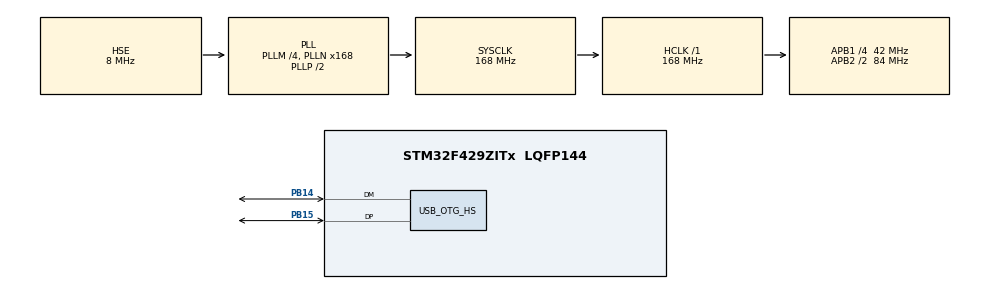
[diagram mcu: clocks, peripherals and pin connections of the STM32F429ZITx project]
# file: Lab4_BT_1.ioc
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FREERTOS.Tasks01=Task01,0,256,StartTask01,Default,NULL,Dynamic,NULL,NULL;Task02,0,128,StartTask02,Default,NULL,Dynamic,NULL,NULL
Mcu.Family=STM32F4
Mcu.Name=STM32F429ZITx
Mcu.Package=LQFP144
NVIC.OTG_HS_IRQn=true\:5\:0\:false\:false\:true\:true\:true\:true\:true
NVIC.PriorityGroup=NVIC_PRIORITYGROUP_4
NVIC.TIM6_DAC_IRQn=true\:15\:0\:false\:false\:true\:false\:false\:true\:true
NVIC.TimeBase=TIM6_DAC_IRQn
NVIC.TimeBaseIP=TIM6
PA13.Mode=Serial_Wire
PA13.Signal=SYS_JTMS-SWDIO
PA14.Mode=Serial_Wire
PA14.Signal=SYS_JTCK-SWCLK
PB14.Mode=Device_Only_FS
PB14.Signal=USB_OTG_HS_DM
PB15.Mode=Device_Only_FS
PB15.Signal=USB_OTG_HS_DP
PH0/OSC_IN.Mode=HSE-External-Oscillator
PH0/OSC_IN.Signal=RCC_OSC_IN
PH1/OSC_OUT.Mode=HSE-External-Oscillator
PH1/OSC_OUT.Signal=RCC_OSC_OUT
ProjectManager.HeapSize=0x2000
ProjectManager.StackSize=0x400
ProjectManager.TargetToolchain=STM32CubeIDE
RCC.48MHZClocksFreq_Value=48000000
RCC.AHBFreq_Value=168000000
RCC.APB1CLKDivider=RCC_HCLK_DIV4
RCC.APB1Freq_Value=42000000
RCC.APB1TimFreq_Value=84000000
RCC.APB2CLKDivider=RCC_HCLK_DIV2
RCC.APB2Freq_Value=84000000
RCC.APB2TimFreq_Value=168000000
RCC.CortexFreq_Value=168000000
RCC.HCLKFreq_Value=168000000
RCC.HSE_VALUE=8000000
RCC.HSI_VALUE=16000000
RCC.LSE_VALUE=32768
RCC.PLLM=4
RCC.PLLN=168
RCC.PLLQ=7
RCC.SYSCLKFreq_VALUE=168000000
RCC.SYSCLKSource=RCC_SYSCLKSOURCE_PLLCLK
RCC.VCOOutputFreq_Value=336000000
USB_DEVICE.CLASS_NAME_HS=CDC
USB_DEVICE.VirtualMode-CDC_HS=Cdc
USB_DEVICE.VirtualModeHS=Cdc_HS
USB_OTG_HS.VirtualMode-Device_Only_FS=Device_Only_FS
VP_FREERTOS_VS_CMSIS_V1.Mode=CMSIS_V1
VP_SYS_VS_tim6.Mode=TIM6
VP_USB_DEVICE_VS_USB_DEVICE_CDC_HS.Mode=CDC_HS
board=custom

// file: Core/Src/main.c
/* USER CODE BEGIN Header */
/**
  ******************************************************************************
  * @file           : main.c
  * @brief          : Main program body
  ******************************************************************************
  * @attention
  *
  * Copyright (c) 2023 STMicroelectronics.
  * All rights reserved.
  *
  * This software is licensed under terms that can be found in the LICENSE file
  * in the root directory of this software component.
  * If no LICENSE file comes with this software, it is provided AS-IS.
  *
  ******************************************************************************
  */
/* USER CODE END Header */
#include "main.h"
#include "cmsis_os.h"
#include "usb_device.h"

/* USER CODE BEGIN Includes */
#include "string.h"
#include "stm32f429i_discovery_sdram.h"
#include "stm32f429i_discovery_lcd.h"
#include "usbd_cdc_if.h"
#include "stm32f429i_discovery_gyroscope.h"
#include "stm32f429i_discovery_io.h"
#include <stdio.h>
/* USER CODE END Includes */

osThreadId Task01Handle;
osThreadId Task02Handle;
/* USER CODE BEGIN PV */
//float valxyz[3];
//uint8_t transmit_d[64];
volatile uint32_t value;
//uint8_t buffer[200];//text buffer

osMailQId(myMailQID);
/* USER CODE END PV */

void SystemClock_Config(void);
static void MX_GPIO_Init(void);
void StartTask01(void const * argument);
void StartTask02(void const * argument);

int main(void)
{

  /* MCU Configuration--------------------------------------------------------*/

  /* Reset of all peripherals, Initializes the Flash interface and the Systick. */
  HAL_Init();

  /* Configure the system clock */
  SystemClock_Config();

  /* Initialize all configured peripherals */
  MX_GPIO_Init();
  /* USER CODE BEGIN 2 */
  BSP_SDRAM_Init();
  *((uint32_t*)SDRAM_DEVICE_ADDR)=0x12345678;
  value=*((uint32_t*)SDRAM_DEVICE_ADDR);
  BSP_LCD_Init();
  BSP_GYRO_Init();
  BSP_LCD_LayerDefaultInit(1, SDRAM_DEVICE_ADDR);
  BSP_LCD_SelectLayer(1);//select on which layer we
  BSP_LCD_DisplayOn();//turn on LCD
  BSP_LCD_Clear(LCD_COLOR_BLACK);//clear the LCD on blACK
  BSP_LCD_SetBackColor(LCD_COLOR_BLACK);//set text background color
  BSP_LCD_SetTextColor(LCD_COLOR_WHITE);//set text color
  /* USER CODE END 2 */

  /* USER CODE BEGIN RTOS_QUEUES */
  /* add queues, ... */

  osMailQDef( myMailQ, 3, float );

  myMailQID = osMailCreate(osMailQ(myMailQ), NULL);

  /* USER CODE END RTOS_QUEUES */

  /* Create the thread(s) */
  /* definition and creation of Task01 */
  osThreadDef(Task01, StartTask01, osPriorityNormal, 0, 256);
  Task01Handle = osThreadCreate(osThread(Task01), NULL);

  /* definition and creation of Task02 */
  osThreadDef(Task02, StartTask02, osPriorityNormal, 0, 128);
  Task02Handle = osThreadCreate(osThread(Task02), NULL);

  /* Start scheduler */
  osKernelStart();

  /* We should never get here as control is now taken by the scheduler */
  /* Infinite loop */
  /* USER CODE BEGIN WHILE */
  while (1)
  {
//
//	  HAL_Delay(1000);
//	  BSP_GYRO_GetXYZ(valxyz);
//	  sprintf(buffer,"xyz:	%f	%f	%f\r\n",valxyz[0],valxyz[1],valxyz[2]);
//	  CDC_Transmit_HS(buffer,64);
//
//
//	  if ((valxyz[0]<0) && (valxyz[1]<0) && (valxyz[2] > 0)){
//		  BSP_LCD_Clear(LCD_COLOR_BLACK);//clear the LCD on blACK
//		  BSP_LCD_DisplayStringAtLine(1,"      ^");
//		  BSP_LCD_DisplayStringAtLine(4,"<");
//	  } else if ((valxyz[0]<0) && (valxyz[1]>0) && (valxyz[2] < 0)){
//		  BSP_LCD_Clear(LCD_COLOR_BLACK);//clear the LCD on blACK
//		  BSP_LCD_DisplayStringAtLine(1,"      ^");
//		  BSP_LCD_DisplayStringAtLine(4,"             >");
//	  } else if (valxyz[0]>0 && valxyz[1]<0 && valxyz[2] < 0){
//		  BSP_LCD_Clear(LCD_COLOR_BLACK);//clear the LCD on blACK
//		  BSP_LCD_DisplayStringAtLine(4,"<");
//		  BSP_LCD_DisplayStringAtLine(8,"      v");
//	  } else if (valxyz[0]>0 && valxyz[1]>0 && valxyz[2] > 0){
//		  BSP_LCD_Clear(LCD_COLOR_BLACK);//clear the LCD on blACK
//		  BSP_LCD_DisplayStringAtLine(4,"             >");
//		  BSP_LCD_DisplayStringAtLine(8,"      v");
//	  }
//
    /* USER CODE END WHILE */

  }
}

void SystemClock_Config(void)
{
  RCC_OscInitTypeDef RCC_OscInitStruct = {0};
  RCC_ClkInitTypeDef RCC_ClkInitStruct = {0};

  /** Configure the main internal regulator output voltage
  */
  __HAL_RCC_PWR_CLK_ENABLE();
  __HAL_PWR_VOLTAGESCALING_CONFIG(PWR_REGULATOR_VOLTAGE_SCALE1);

  /** Initializes the RCC Oscillators according to the specified parameters
  * in the RCC_OscInitTypeDef structure.
  */
  RCC_OscInitStruct.OscillatorType = RCC_OSCILLATORTYPE_HSE;
  RCC_OscInitStruct.HSEState = RCC_HSE_ON;
  RCC_OscInitStruct.PLL.PLLState = RCC_PLL_ON;
  RCC_OscInitStruct.PLL.PLLSource = RCC_PLLSOURCE_HSE;
  RCC_OscInitStruct.PLL.PLLM = 4;
  RCC_OscInitStruct.PLL.PLLN = 168;
  RCC_OscInitStruct.PLL.PLLP = RCC_PLLP_DIV2;
  RCC_OscInitStruct.PLL.PLLQ = 7;
  if (HAL_RCC_OscConfig(&RCC_OscInitStruct) != HAL_OK)
  {
    Error_Handler();
  }

  /** Initializes the CPU, AHB and APB buses clocks
  */
  RCC_ClkInitStruct.ClockType = RCC_CLOCKTYPE_HCLK|RCC_CLOCKTYPE_SYSCLK
                              |RCC_CLOCKTYPE_PCLK1|RCC_CLOCKTYPE_PCLK2;
  RCC_ClkInitStruct.SYSCLKSource = RCC_SYSCLKSOURCE_PLLCLK;
  RCC_ClkInitStruct.AHBCLKDivider = RCC_SYSCLK_DIV1;
  RCC_ClkInitStruct.APB1CLKDivider = RCC_HCLK_DIV4;
  RCC_ClkInitStruct.APB2CLKDivider = RCC_HCLK_DIV2;

  if (HAL_RCC_ClockConfig(&RCC_ClkInitStruct, FLASH_LATENCY_5) != HAL_OK)
  {
    Error_Handler();
  }
}

static void MX_GPIO_Init(void)
{

  /* GPIO Ports Clock Enable */
  __HAL_RCC_GPIOH_CLK_ENABLE();
  __HAL_RCC_GPIOB_CLK_ENABLE();
  __HAL_RCC_GPIOA_CLK_ENABLE();

}

void StartTask01(void const * argument)
{
  /* init code for USB_DEVICE */
  MX_USB_DEVICE_Init();
  /* USER CODE BEGIN 5 */
	uint8_t buffer[200];//text buffer
	osSignalWait(0x1, osWaitForever);
	osSignalSet(Task02Handle, 0x1);
  /* Infinite loop */
  for(;;)
  {
	  osEvent event = osMailGet(myMailQID, osWaitForever); //Get mail
	  float *valxyz = event.value.p;
	  sprintf(buffer,"xyz:	%f	%f	%f\r\n",valxyz[0],valxyz[1],valxyz[2]);
	  osMailFree(myMailQID, valxyz); //Free mail queue memory
	  CDC_Transmit_HS(buffer,64);
  }
  for(;;){
  		  osDelay(1);
  	  }
  /* USER CODE END 5 */
}

void StartTask02(void const * argument)
{
  /* USER CODE BEGIN StartTask02 */
  /* Infinite loop */
	if (BSP_GYRO_Init() != GYRO_OK)
	  {
	    Error_Handler();
	  }
	float valxyz[3];

	osSignalWait(0x1, osWaitForever);
  for(;;)
  {
	  BSP_GYRO_GetXYZ(valxyz);
	  float *transmit_d;
	  transmit_d = NULL;
	  do
	      {
	        transmit_d = (float *)osMailAlloc(myMailQID, osWaitForever); //Allocate memory slot
	      } while (NULL == transmit_d);

	  transmit_d = valxyz;

	  osMailPut(myMailQID, transmit_d); //Put data into mail queue. Check cmsis_os.c for API named
	  if ((valxyz[0]<0) && (valxyz[1]<0) && (valxyz[2] > 0)){
		  BSP_LCD_Clear(LCD_COLOR_BLACK);//clear the LCD on blACK
		  BSP_LCD_DisplayStringAtLine(1,"      ^");
		  BSP_LCD_DisplayStringAtLine(4,"<");
	  } else if ((valxyz[0] <0) && (valxyz[1]>0) && (valxyz[2] < 0)){
		  BSP_LCD_Clear(LCD_COLOR_BLACK);//clear the LCD on blACK
		  BSP_LCD_DisplayStringAtLine(1,"      ^");
		  BSP_LCD_DisplayStringAtLine(4,"             >");
	  } else if (valxyz[0] > 0 && valxyz[1] < 0 && valxyz[2] < 0){
		  BSP_LCD_Clear(LCD_COLOR_BLACK);//clear the LCD on blACK
		  BSP_LCD_DisplayStringAtLine(4,"<");
		  BSP_LCD_DisplayStringAtLine(8,"      v");
	  } else if (valxyz[0] >0 && valxyz[1] >0 && valxyz[2] > 0){
		  BSP_LCD_Clear(LCD_COLOR_BLACK);//clear the LCD on blACK
		  BSP_LCD_DisplayStringAtLine(4,"             >");
		  BSP_LCD_DisplayStringAtLine(8,"      v");
	  } else {
		  BSP_LCD_Clear(LCD_COLOR_BLACK);//clear the LCD on blACK
		  BSP_LCD_DisplayStringAtLine(4,"      *");
	  }
	  free(transmit_d);
  }
  for(;;){
    		  osDelay(1);
    	  }
  /* USER CODE END StartTask02 */
}

void HAL_TIM_PeriodElapsedCallback(TIM_HandleTypeDef *htim)
{
  if (htim->Instance == TIM6) {
    HAL_IncTick();
  }
}

void Error_Handler(void)
{
  __disable_irq();
  while (1)
  {
  }
}
